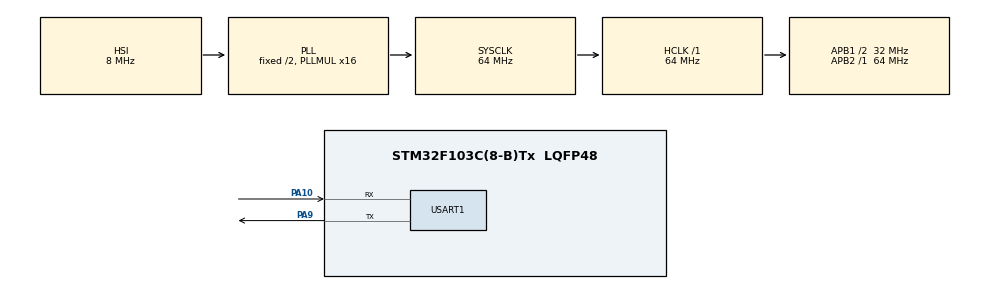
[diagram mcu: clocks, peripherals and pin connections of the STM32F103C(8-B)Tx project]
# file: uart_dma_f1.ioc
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Dma.Request0=USART1_RX
Dma.USART1_RX.0.Direction=DMA_PERIPH_TO_MEMORY
Dma.USART1_RX.0.Instance=DMA1_Channel5
Dma.USART1_RX.0.MemDataAlignment=DMA_MDATAALIGN_BYTE
Dma.USART1_RX.0.MemInc=DMA_MINC_ENABLE
Dma.USART1_RX.0.Mode=DMA_CIRCULAR
Dma.USART1_RX.0.PeriphDataAlignment=DMA_PDATAALIGN_BYTE
Dma.USART1_RX.0.PeriphInc=DMA_PINC_DISABLE
Dma.USART1_RX.0.Priority=DMA_PRIORITY_LOW
Mcu.Family=STM32F1
Mcu.Name=STM32F103C(8-B)Tx
Mcu.Package=LQFP48
NVIC.DMA1_Channel5_IRQn=true\:0\:0\:false\:false\:true\:false\:true\:true
NVIC.PriorityGroup=NVIC_PRIORITYGROUP_4
NVIC.USART1_IRQn=true\:0\:0\:false\:false\:true\:true\:true\:true
PA10.Mode=Asynchronous
PA10.Signal=USART1_RX
PA13.Mode=Serial_Wire
PA13.Signal=SYS_JTMS-SWDIO
PA14.Mode=Serial_Wire
PA14.Signal=SYS_JTCK-SWCLK
PA9.Mode=Asynchronous
PA9.Signal=USART1_TX
ProjectManager.HeapSize=0x200
ProjectManager.StackSize=0x400
ProjectManager.TargetToolchain=STM32CubeIDE
RCC.AHBFreq_Value=64000000
RCC.APB1CLKDivider=RCC_HCLK_DIV2
RCC.APB1Freq_Value=32000000
RCC.APB1TimFreq_Value=64000000
RCC.APB2Freq_Value=64000000
RCC.APB2TimFreq_Value=64000000
RCC.HCLKFreq_Value=64000000
RCC.PLLMUL=RCC_PLL_MUL16
RCC.SYSCLKFreq_VALUE=64000000
RCC.SYSCLKSource=RCC_SYSCLKSOURCE_PLLCLK
RCC.USBFreq_Value=64000000
USART1.VirtualMode=VM_ASYNC
VP_CRC_VS_CRC.Mode=CRC_Activate
board=custom

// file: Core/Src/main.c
/* USER CODE BEGIN Header */
/**
  ******************************************************************************
  * @file           : main.c
  * @brief          : Main program body
  ******************************************************************************
  * @attention
  *
  * Copyright (c) 2024 STMicroelectronics.
  * All rights reserved.
  *
  * This software is licensed under terms that can be found in the LICENSE file
  * in the root directory of this software component.
  * If no LICENSE file comes with this software, it is provided AS-IS.
  *
  ******************************************************************************
  */
/* USER CODE END Header */
#include "main.h"

/* USER CODE BEGIN Includes */
uint8_t tx_buff[]={65,66,67,68,69,70,71,72,73,74}; //ABCDEFGHIJ in ASCII code
uint8_t usart_rx_dma_buffer[64];
#define ARRAY_LEN(x)            (sizeof(x) / sizeof((x)[0]))
uint16_t HowManyDataPackArrive=0;
uint8_t ArrivedDataLengs[100];

/* USER CODE END Includes */

CRC_HandleTypeDef hcrc;

void SystemClock_Config(void);
static void MX_GPIO_Init(void);
static void MX_DMA_Init(void);
static void MX_USART1_UART_Init(void);
static void MX_CRC_Init(void);

int main(void)
{

  /* MCU Configuration--------------------------------------------------------*/

  /* Reset of all peripherals, Initializes the Flash interface and the Systick. */
  HAL_Init();

  /* Configure the system clock */
  SystemClock_Config();

  /* Initialize all configured peripherals */
  MX_GPIO_Init();
  MX_DMA_Init();
  MX_USART1_UART_Init();
  MX_CRC_Init();

  /* Infinite loop */
  while (1)
  {

    /* USER CODE BEGIN 3 */
	  uint8_t Test[] = "Hello World !!!\r\n"; //Data to send
	  //HAL_UART_Transmit(&huart1,Test,sizeof(Test),10);// Sending in normal mode
	  HAL_Delay(1000);
  }
  /* USER CODE END 3 */
}

void SystemClock_Config(void)
{
  RCC_OscInitTypeDef RCC_OscInitStruct = {0};
  RCC_ClkInitTypeDef RCC_ClkInitStruct = {0};

  /** Initializes the RCC Oscillators according to the specified parameters
  * in the RCC_OscInitTypeDef structure.
  */
  RCC_OscInitStruct.OscillatorType = RCC_OSCILLATORTYPE_HSI;
  RCC_OscInitStruct.HSIState = RCC_HSI_ON;
  RCC_OscInitStruct.HSICalibrationValue = RCC_HSICALIBRATION_DEFAULT;
  RCC_OscInitStruct.PLL.PLLState = RCC_PLL_ON;
  RCC_OscInitStruct.PLL.PLLSource = RCC_PLLSOURCE_HSI_DIV2;
  RCC_OscInitStruct.PLL.PLLMUL = RCC_PLL_MUL16;
  if (HAL_RCC_OscConfig(&RCC_OscInitStruct) != HAL_OK)
  {
    Error_Handler();
  }

  /** Initializes the CPU, AHB and APB buses clocks
  */
  RCC_ClkInitStruct.ClockType = RCC_CLOCKTYPE_HCLK|RCC_CLOCKTYPE_SYSCLK
                              |RCC_CLOCKTYPE_PCLK1|RCC_CLOCKTYPE_PCLK2;
  RCC_ClkInitStruct.SYSCLKSource = RCC_SYSCLKSOURCE_PLLCLK;
  RCC_ClkInitStruct.AHBCLKDivider = RCC_SYSCLK_DIV1;
  RCC_ClkInitStruct.APB1CLKDivider = RCC_HCLK_DIV2;
  RCC_ClkInitStruct.APB2CLKDivider = RCC_HCLK_DIV1;

  if (HAL_RCC_ClockConfig(&RCC_ClkInitStruct, FLASH_LATENCY_2) != HAL_OK)
  {
    Error_Handler();
  }
}

static void MX_CRC_Init(void)
{

  hcrc.Instance = CRC;
  if (HAL_CRC_Init(&hcrc) != HAL_OK)
  {
    Error_Handler();
  }

}

static void MX_USART1_UART_Init(void)
{

  LL_USART_InitTypeDef USART_InitStruct = {0};

  LL_GPIO_InitTypeDef GPIO_InitStruct = {0};

  /* Peripheral clock enable */
  LL_APB2_GRP1_EnableClock(LL_APB2_GRP1_PERIPH_USART1);

  LL_APB2_GRP1_EnableClock(LL_APB2_GRP1_PERIPH_GPIOA);
  /**USART1 GPIO Configuration
  PA9   ------> USART1_TX
  PA10   ------> USART1_RX
  */
  GPIO_InitStruct.Pin = LL_GPIO_PIN_9;
  GPIO_InitStruct.Mode = LL_GPIO_MODE_ALTERNATE;
  GPIO_InitStruct.Speed = LL_GPIO_SPEED_FREQ_HIGH;
  GPIO_InitStruct.OutputType = LL_GPIO_OUTPUT_PUSHPULL;
  LL_GPIO_Init(GPIOA, &GPIO_InitStruct);

  GPIO_InitStruct.Pin = LL_GPIO_PIN_10;
  GPIO_InitStruct.Mode = LL_GPIO_MODE_FLOATING;
  LL_GPIO_Init(GPIOA, &GPIO_InitStruct);

  /* USART1 DMA Init */

  /* USART1_RX Init */
  LL_DMA_SetDataTransferDirection(DMA1, LL_DMA_CHANNEL_5, LL_DMA_DIRECTION_PERIPH_TO_MEMORY);

  LL_DMA_SetChannelPriorityLevel(DMA1, LL_DMA_CHANNEL_5, LL_DMA_PRIORITY_LOW);

  LL_DMA_SetMode(DMA1, LL_DMA_CHANNEL_5, LL_DMA_MODE_CIRCULAR);

  LL_DMA_SetPeriphIncMode(DMA1, LL_DMA_CHANNEL_5, LL_DMA_PERIPH_NOINCREMENT);

  LL_DMA_SetMemoryIncMode(DMA1, LL_DMA_CHANNEL_5, LL_DMA_MEMORY_INCREMENT);

  LL_DMA_SetPeriphSize(DMA1, LL_DMA_CHANNEL_5, LL_DMA_PDATAALIGN_BYTE);

  LL_DMA_SetMemorySize(DMA1, LL_DMA_CHANNEL_5, LL_DMA_MDATAALIGN_BYTE);

  LL_DMA_SetPeriphAddress(DMA1, LL_DMA_CHANNEL_5, LL_USART_DMA_GetRegAddr(USART1));
  LL_DMA_SetMemoryAddress(DMA1, LL_DMA_CHANNEL_5, (uint32_t)usart_rx_dma_buffer);
  LL_DMA_SetDataLength(DMA1, LL_DMA_CHANNEL_5, ARRAY_LEN(usart_rx_dma_buffer));

  /* Enable HT & TC interrupts */
  LL_DMA_EnableIT_HT(DMA1, LL_DMA_CHANNEL_5);
  LL_DMA_EnableIT_TC(DMA1, LL_DMA_CHANNEL_5);

  /* USART1 interrupt Init */
  NVIC_SetPriority(USART1_IRQn, NVIC_EncodePriority(NVIC_GetPriorityGrouping(),0, 0));
  NVIC_EnableIRQ(USART1_IRQn);

  USART_InitStruct.BaudRate = 115200;
  USART_InitStruct.DataWidth = LL_USART_DATAWIDTH_8B;
  USART_InitStruct.StopBits = LL_USART_STOPBITS_1;
  USART_InitStruct.Parity = LL_USART_PARITY_NONE;
  USART_InitStruct.TransferDirection = LL_USART_DIRECTION_TX_RX;
  USART_InitStruct.HardwareFlowControl = LL_USART_HWCONTROL_NONE;
  USART_InitStruct.OverSampling = LL_USART_OVERSAMPLING_16;
  LL_USART_Init(USART1, &USART_InitStruct);
  LL_USART_ConfigAsyncMode(USART1);

  LL_USART_Enable(USART1);
  /* USER CODE BEGIN USART1_Init 2 */
  LL_USART_EnableDMAReq_RX(USART1);
  LL_USART_EnableIT_IDLE(USART1);

  /* Enable USART and DMA */
  LL_DMA_EnableChannel(DMA1, LL_DMA_CHANNEL_5);
  LL_USART_Enable(USART1);
  /* USER CODE END USART1_Init 2 */

}

static void MX_DMA_Init(void)
{

  /* Init with LL driver */
  /* DMA controller clock enable */
  LL_AHB1_GRP1_EnableClock(LL_AHB1_GRP1_PERIPH_DMA1);

  /* DMA interrupt init */
  /* DMA1_Channel5_IRQn interrupt configuration */
  NVIC_SetPriority(DMA1_Channel5_IRQn, NVIC_EncodePriority(NVIC_GetPriorityGrouping(),0, 0));
  NVIC_EnableIRQ(DMA1_Channel5_IRQn);

}

static void MX_GPIO_Init(void)
{

  /* GPIO Ports Clock Enable */
  __HAL_RCC_GPIOA_CLK_ENABLE();

}

/* USER CODE BEGIN 4 */

void usart_rx_check(void)
{
    static size_t old_pos;

	size_t pos;
	size_t dmaWhatPose=LL_DMA_GetDataLength(DMA1, LL_DMA_CHANNEL_5);
	 pos = ARRAY_LEN(usart_rx_dma_buffer) - LL_DMA_GetDataLength(DMA1, LL_DMA_CHANNEL_5);
	 if (pos != old_pos) {
		 if (pos > old_pos) {

			 usart_process_data(&usart_rx_dma_buffer[old_pos], pos - old_pos,false,-1);

	         }
	         else {
	         	 usart_process_data(&usart_rx_dma_buffer[old_pos], ARRAY_LEN(usart_rx_dma_buffer) - old_pos,false,-1);
	         	 if (pos > 0) {
	         		 usart_process_data(&usart_rx_dma_buffer[0], pos,false,-1);
	         	  }
	         }
		 old_pos = pos;
	 }
}

void usart_process_data(const void* data, size_t len,bool isOwerFlow,int newPos) {
    const uint8_t* d = data;
    char proccesBuffer[len];
    /*
     * This function is called on DMA TC or HT events, and on UART IDLE (if enabled) event.
     *
     * For the sake of this example, function does a loop-back data over UART in polling mode.
     * Check ringbuff RX-based example for implementation with TX & RX DMA transfer.
     */

	for (; len > 0; --len, ++d) {
		if(parserRx(*d))
		{
			//Tam bir data geldi işleme konabilir
			HowManyDataPackArrive++;
			uart_state=0; // ye
		}
	}

	/*
    for (; len > 0; --len, ++d) {
        LL_USART_TransmitData8(USART1, *d);
        while (!LL_USART_IsActiveFlag_TXE(USART1)) {}
    }
    */
    reverseString(proccesBuffer);

    while (!LL_USART_IsActiveFlag_TC(USART1)) {}
}

void reverseString(char* str) {

    int length = strlen(str);
    for (int i = 0; i < length / 2; i++) {
        char temp = str[i];
        str[i] = str[length - i - 1];
        str[length - i - 1] = temp;
    }
}
/* USER CODE END 4 */

void Error_Handler(void)
{
  __disable_irq();
  while (1)
  {
  }
}
